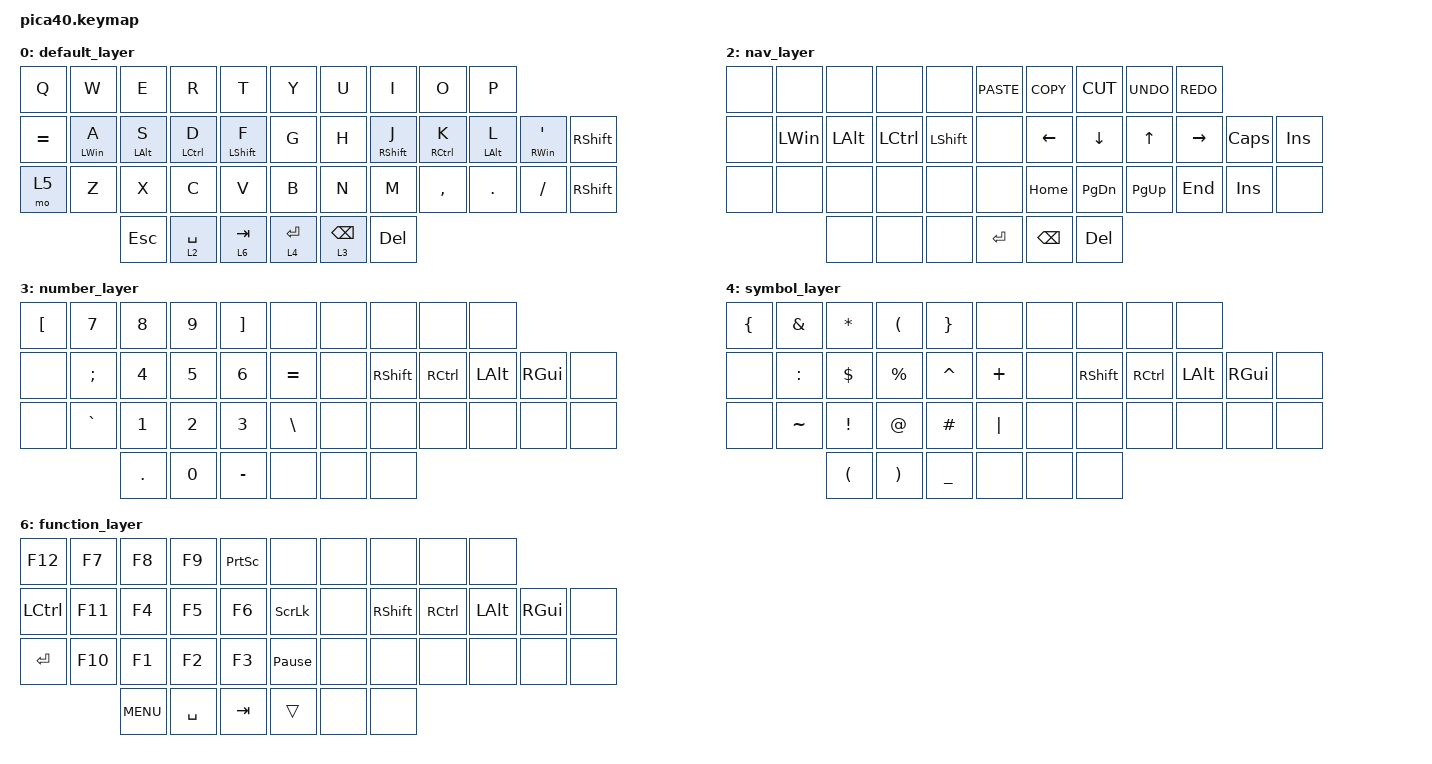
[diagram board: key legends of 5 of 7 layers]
#include <behaviors.dtsi>
#include <dt-bindings/zmk/bt.h>
#include <dt-bindings/zmk/keys.h>

#define QWERTY 0
#define GAME 1
#define NAV 2
#define NUM 3
#define SYM 4
#define FUNC 5

&mt {
    tapping-term-ms = <160>;
    flavor = "tap-preferred";
};

&lt {
    tapping-term-ms = <160>;
    flavor = "tap-preferred";
};

/ {
    behaviors {
        hm: homerow_mods {
            compatible = "zmk,behavior-hold-tap";
            label = "HOMEROW_MODS";
            #binding-cells = <2>;
            tapping-term-ms = <160>;
            quick-tap-ms = <0>;
            flavor = "tap-preferred";
            bindings = <&kp>, <&kp>;
        };

        hr: homerow_mods_ring_finger {
            compatible = "zmk,behavior-hold-tap";
            label = "HOMEROW_MODS_RING_FINGER";
            #binding-cells = <2>;
            tapping-term-ms = <190>;
            quick-tap-ms = <0>;
            flavor = "tap-preferred";
            bindings = <&kp>, <&kp>;
        };

        hp: homerow_mods_pinky_finger {
            compatible = "zmk,behavior-hold-tap";
            label = "HOMEROW_MODS_PINKY_FINGER";
            #binding-cells = <2>;
            tapping-term-ms = <220>;
            quick-tap-ms = <0>;
            flavor = "tap-preferred";
            bindings = <&kp>, <&kp>;
        };

        tm: thumb_mods {
            compatible = "zmk,behavior-hold-tap";
            label = "THUMB_MODS";
            #binding-cells = <2>;
            tapping-term-ms = <160>;
            quick-tap-ms = <160>;
            flavor = "tap-preferred";
            bindings = <&kp>, <&kp>;
        };

        lh: layer_hold {
            compatible = "zmk,behavior-hold-tap";
            label = "LAYER_HOLD";
            #binding-cells = <2>;
            tapping-term-ms = <160>;
            quick-tap-ms = <160>;
            flavor = "tap-preferred";
            bindings = <&mo>, <&kp>;
        };

        // Easy alt-tab with alt+backspace thumb using mod-morphs

        bstab: backspace_tab {
            compatible = "zmk,behavior-mod-morph";
            label = "BSPC_TAB";
            #binding-cells = <0>;
            bindings = <&kp BSPC>, <&kp TAB>;

            mods = <MOD_LALT>;
        };

        lt_bspc: layer_tap_backspace_tab {
            compatible = "zmk,behavior-hold-tap";
            label = "LT_BT";
            #binding-cells = <2>;
            tapping-term-ms = <150>;
            flavor = "balanced";
            bindings = <&mo>, <&bstab>;
        };
    };

    combos {
        compatible = "zmk,combos";

        Esccombo {
            bindings = <&lt 0 ESCAPE>;
            key-positions = <35 36>;
        };

        Deletecombo {
            bindings = <&lt 5 DELETE>;
            key-positions = <37 38>;
        };
    };

    keymap {
        compatible = "zmk,keymap";

        default_layer {
            bindings = <
&kp Q      &kp W           &kp E       &kp R        &kp T        &kp Y         &kp U            &kp I        &kp O        &kp P
&kp EQUAL  &hp LEFT_WIN A  &hr LALT S  &hm LCTRL D  &hm LSHFT F  &kp G         &kp H            &hm RSHFT J  &hm RCTRL K  &hr LALT L  &hp RIGHT_WIN SQT  &kp RSHFT
&mo 5      &kp Z           &kp X       &kp C        &kp V        &kp B         &kp N            &kp M        &kp COMMA    &kp DOT     &kp FSLH           &kp RSHIFT
                           &kp ESCAPE  &lt 2 SPACE  &lh 6 TAB    &lt 4 RETURN  &lh 3 BACKSPACE  &kp DELETE
            >;

            sensor-bindings = <&inc_dec_kp C_VOL_DN C_VOL_UP>;
        };

        layer_6 {
            bindings = <
&kp Q    &kp W  &kp E      &kp R         &kp T           &kp Y    &kp U     &kp I    &kp O      &kp P
&kp TAB  &kp A  &kp S      &kp D         &kp F           &kp G    &kp H     &kp J    &kp K      &kp L    &kp SQT   &none
&mo 5    &kp Z  &kp X      &kp C         &kp V           &kp B    &kp N     &kp M    &kp COMMA  &kp DOT  &kp FSLH  &kp RCTRL
                &kp LCTRL  &kp LEFT_ALT  &kp LEFT_SHIFT  &kp RET  &kp BSPC  &kp DEL  &trans     &trans
            >;
        };

        nav_layer {
            bindings = <
&none  &none         &none     &none      &none      &kp K_PASTE  &kp K_COPY     &kp K_CUT      &kp K_UNDO    &kp K_REDO
&none  &kp LEFT_WIN  &kp LALT  &kp LCTRL  &kp LSHFT  &none        &kp LEFT       &kp DOWN       &kp UP_ARROW  &kp RIGHT   &kp CAPSLOCK  &kp INS
&none  &none         &none     &none      &none      &none        &kp HOME       &kp PAGE_DOWN  &kp PAGE_UP   &kp END     &kp INSERT    &none
                     &none     &none      &none      &kp RETURN   &kp BACKSPACE  &kp DELETE
            >;

            sensor-bindings = <&inc_dec_kp K_SCROLL_UP K_SCROLL_DOWN>;
        };

        number_layer {
            bindings = <
&kp LEFT_BRACKET  &kp N7     &kp N8      &kp N9        &kp RIGHT_BRACKET  &none          &none  &none      &none      &none
&none             &kp SEMI   &kp N4      &kp N5        &kp N6             &kp EQUAL      &none  &kp RSHFT  &kp RCTRL  &kp LALT  &kp RGUI  &none
&none             &kp GRAVE  &kp N1      &kp N2        &kp N3             &kp BACKSLASH  &none  &none      &none      &none     &none     &none
                             &kp PERIOD  &kp NUMBER_0  &kp MINUS          &none          &none  &none
            >;
        };

        symbol_layer {
            bindings = <
&kp LEFT_BRACE  &kp AMPS   &kp STAR              &kp LPAR               &kp RIGHT_BRACE  &none     &none  &none      &none      &none
&none           &kp COLON  &kp DLLR              &kp PRCNT              &kp CARET        &kp PLUS  &none  &kp RSHFT  &kp RCTRL  &kp LALT  &kp RGUI  &none
&none           &kp TILDE  &kp EXCL              &kp AT                 &kp HASH         &kp PIPE  &none  &none      &none      &none     &none     &none
                           &kp LEFT_PARENTHESIS  &kp RIGHT_PARENTHESIS  &kp UNDERSCORE   &none     &none  &none
            >;
        };

        Media {
            bindings = <
&trans  &kp N7  &kp N8  &kp N9  &trans  &bt BT_CLR  &trans      &trans        &trans        &trans
&trans  &trans  &kp N4  &kp N5  &kp N6  &trans      &trans      &trans        &trans        &trans        &trans        &tog 1
&none   &trans  &kp N1  &kp N2  &kp N3  &trans      &trans      &bt BT_SEL 0  &bt BT_SEL 1  &bt BT_SEL 2  &bt BT_SEL 3  &trans
                &trans  &kp N0  &mo 6   &trans      &bt BT_CLR  &bt BT_CLR    &trans        &trans
            >;
        };

        function_layer {
            bindings = <
&kp F12    &kp F7   &kp F8      &kp F9     &kp PSCRN  &none            &none  &none      &none      &none
&kp LCTRL  &kp F11  &kp F4      &kp F5     &kp F6     &kp SCROLLLOCK   &none  &kp RSHFT  &kp RCTRL  &kp LALT  &kp RGUI  &none
&kp ENTER  &kp F10  &kp F1      &kp F2     &kp F3     &kp PAUSE_BREAK  &none  &none      &none      &none     &none     &none
                    &kp K_MENU  &kp SPACE  &kp TAB    &trans           &none  &none
            >;
        };
    };
};
